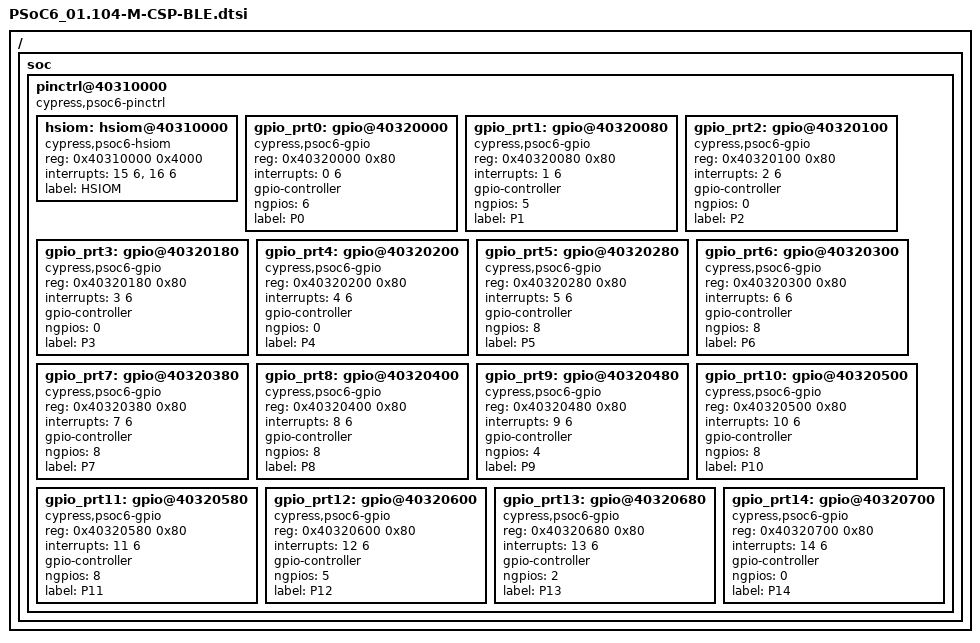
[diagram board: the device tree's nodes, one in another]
/*
 * Copyright (c) 2021, Cypress Semiconductor
 * 
 * SPDX-License-Identifier: Apache-2.0
 */

#include <dt-bindings/gpio/gpio.h>
#include <PSoC6_01.dtsi>

/ {
    soc {
        pinctrl@40310000 {
            compatible = "cypress,psoc6-pinctrl";
            ranges = <0x40310000 0x20000>;

            hsiom: hsiom@40310000 {
                compatible = "cypress,psoc6-hsiom";
                reg = <0x40310000 0x4000>;
                interrupts = <15 6>, <16 6>;
                label = "HSIOM";
                status = "okay";
            };

            gpio_prt0: gpio@40320000 {
                compatible = "cypress,psoc6-gpio";
                reg = <0x40320000 0x80>;
                interrupts = <0 6>;
                gpio-controller;
                ngpios = <6>;
                status = "okay";
                label = "P0";
            };
            gpio_prt1: gpio@40320080 {
                compatible = "cypress,psoc6-gpio";
                reg = <0x40320080 0x80>;
                interrupts = <1 6>;
                gpio-controller;
                ngpios = <5>;
                status = "okay";
                label = "P1";
            };
            gpio_prt2: gpio@40320100 {
                compatible = "cypress,psoc6-gpio";
                reg = <0x40320100 0x80>;
                interrupts = <2 6>;
                gpio-controller;
                ngpios = <0>;
                status = "okay";
                label = "P2";
            };
            gpio_prt3: gpio@40320180 {
                compatible = "cypress,psoc6-gpio";
                reg = <0x40320180 0x80>;
                interrupts = <3 6>;
                gpio-controller;
                ngpios = <0>;
                status = "okay";
                label = "P3";
            };
            gpio_prt4: gpio@40320200 {
                compatible = "cypress,psoc6-gpio";
                reg = <0x40320200 0x80>;
                interrupts = <4 6>;
                gpio-controller;
                ngpios = <0>;
                status = "okay";
                label = "P4";
            };
            gpio_prt5: gpio@40320280 {
                compatible = "cypress,psoc6-gpio";
                reg = <0x40320280 0x80>;
                interrupts = <5 6>;
                gpio-controller;
                ngpios = <8>;
                status = "okay";
                label = "P5";
            };
            gpio_prt6: gpio@40320300 {
                compatible = "cypress,psoc6-gpio";
                reg = <0x40320300 0x80>;
                interrupts = <6 6>;
                gpio-controller;
                ngpios = <8>;
                status = "okay";
                label = "P6";
            };
            gpio_prt7: gpio@40320380 {
                compatible = "cypress,psoc6-gpio";
                reg = <0x40320380 0x80>;
                interrupts = <7 6>;
                gpio-controller;
                ngpios = <8>;
                status = "okay";
                label = "P7";
            };
            gpio_prt8: gpio@40320400 {
                compatible = "cypress,psoc6-gpio";
                reg = <0x40320400 0x80>;
                interrupts = <8 6>;
                gpio-controller;
                ngpios = <8>;
                status = "okay";
                label = "P8";
            };
            gpio_prt9: gpio@40320480 {
                compatible = "cypress,psoc6-gpio";
                reg = <0x40320480 0x80>;
                interrupts = <9 6>;
                gpio-controller;
                ngpios = <4>;
                status = "okay";
                label = "P9";
            };
            gpio_prt10: gpio@40320500 {
                compatible = "cypress,psoc6-gpio";
                reg = <0x40320500 0x80>;
                interrupts = <10 6>;
                gpio-controller;
                ngpios = <8>;
                status = "okay";
                label = "P10";
            };
            gpio_prt11: gpio@40320580 {
                compatible = "cypress,psoc6-gpio";
                reg = <0x40320580 0x80>;
                interrupts = <11 6>;
                gpio-controller;
                ngpios = <8>;
                status = "okay";
                label = "P11";
            };
            gpio_prt12: gpio@40320600 {
                compatible = "cypress,psoc6-gpio";
                reg = <0x40320600 0x80>;
                interrupts = <12 6>;
                gpio-controller;
                ngpios = <5>;
                status = "okay";
                label = "P12";
            };
            gpio_prt13: gpio@40320680 {
                compatible = "cypress,psoc6-gpio";
                reg = <0x40320680 0x80>;
                interrupts = <13 6>;
                gpio-controller;
                ngpios = <2>;
                status = "okay";
                label = "P13";
            };
            gpio_prt14: gpio@40320700 {
                compatible = "cypress,psoc6-gpio";
                reg = <0x40320700 0x80>;
                interrupts = <14 6>;
                gpio-controller;
                ngpios = <0>;
                status = "okay";
                label = "P14";
            };

        };
    };
};
